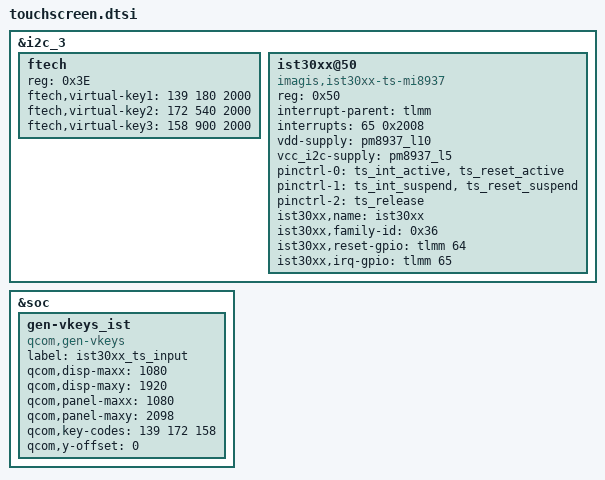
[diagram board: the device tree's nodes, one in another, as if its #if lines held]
&i2c_3 {
	/delete-node/ synaptics@4b;

	ftech {
		reg = <0x3E>;
#ifndef CONFIG_TOUCHSCREEN_FTS_MI8937
		ftech,virtual-key1 = <139 180 2000>;/*menu*/
		ftech,virtual-key2 = <172 540 2000>;/*home*/
		ftech,virtual-key3 = <158 900 2000>;/*back*/
#endif
	};

	ist30xx@50 {
#ifdef CONFIG_TOUCHSCREEN_IST30XX_MI8937
		compatible = "imagis,ist30xx-ts-mi8937";
#else
		compatible = "imagis,ist30xx-ts";
#endif
		reg = <0x50>;
		interrupt-parent = <&tlmm>;
		interrupts = <65 0x2008>;
		vdd-supply = <&pm8937_l10>;
		vcc_i2c-supply = <&pm8937_l5>;
		pinctrl-names = "pmx_ts_active","pmx_ts_suspend",
			"pmx_ts_release";
		pinctrl-0 = <&ts_int_active &ts_reset_active>;
		pinctrl-1 = <&ts_int_suspend &ts_reset_suspend>;
		pinctrl-2 = <&ts_release>;
		ist30xx,name = "ist30xx";
		ist30xx,family-id = <0x36>;
		ist30xx,reset-gpio = <&tlmm 64 0x00>;
		ist30xx,irq-gpio = <&tlmm 65 0x2008>;
	};
};

&soc {
	gen-vkeys_ist {
#ifdef CONFIG_TOUCHSCREEN_FTS_MI8937
		compatible = "qcom,gen-vkeys";
#else
		compatible = "qcom,gen-vkeys_ist";
#endif
		label = "ist30xx_ts_input";
		qcom,disp-maxx = <1080>;
		qcom,disp-maxy = <1920>;
		qcom,panel-maxx = <1080>;
		qcom,panel-maxy = <2098>;
		qcom,key-codes = <139 172 158>;
		qcom,y-offset = <0>;
	};
};
